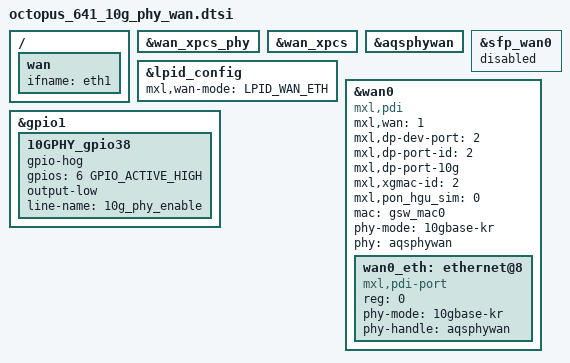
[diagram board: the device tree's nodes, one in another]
// SPDX-License-Identifier: GPL-2.0
/*
 * Copyright (C) 2023 MaxLinear, Inc.
 */

/ {
	wan {
		ifname = "eth1";
	};
};

/* WAN XPCS PHY */
&wan_xpcs_phy {
	status = "okay";
};

&wan_xpcs {
	status = "okay";
};

&aqsphywan {
	status = "okay";
};

&sfp_wan0 {
	status = "disabled";
};

&lpid_config {
	mxl,wan-mode = <LPID_WAN_ETH>;
};

&wan0 {
	status = "okay";

	#address-cells = <1>;
	#size-cells = <0>;
	compatible = "mxl,pdi";
	mxl,wan = <1>;
	mxl,dp-dev-port = <2>;
	mxl,dp-port-id = <2>;
	mxl,dp-port-10g;
	mxl,xgmac-id = <2>;
	mxl,pon_hgu_sim = <0>;
	mac = <&gsw_mac0>;
	phy-mode = "10gbase-kr";
	phy = <&aqsphywan>;

	wan0_eth: ethernet@8 {
		compatible = "mxl,pdi-port";
		reg = <0>;
		phy-mode = "10gbase-kr";
		phy-handle = <&aqsphywan>;
	};
};

&gpio1 {
	10GPHY_gpio38 {
		gpio-hog;
		gpios = <6 GPIO_ACTIVE_HIGH>;
		output-low;
		line-name = "10g_phy_enable";
	};
};

